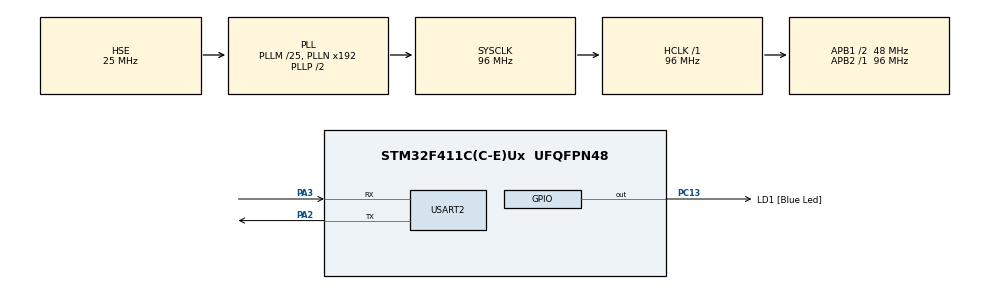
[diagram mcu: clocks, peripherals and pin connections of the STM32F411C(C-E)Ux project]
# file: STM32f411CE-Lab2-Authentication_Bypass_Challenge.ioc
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Mcu.Family=STM32F4
Mcu.Name=STM32F411C(C-E)Ux
Mcu.Package=UFQFPN48
NVIC.PriorityGroup=NVIC_PRIORITYGROUP_4
PA13.Mode=JTAG_5_pins
PA13.Signal=SYS_JTMS-SWDIO
PA14.Mode=JTAG_5_pins
PA14.Signal=SYS_JTCK-SWCLK
PA15.Mode=JTAG_5_pins
PA15.Signal=SYS_JTDI
PA2.Mode=Asynchronous
PA2.Signal=USART2_TX
PA3.Mode=Asynchronous
PA3.Signal=USART2_RX
PB3.Mode=JTAG_5_pins
PB3.Signal=SYS_JTDO-SWO
PB4.Mode=JTAG_5_pins
PB4.Signal=SYS_JTRST
PC13-ANTI_TAMP.GPIO_Label=LD1 [Blue Led]
PC13-ANTI_TAMP.Signal=GPIO_Output
PC14-OSC32_IN.Mode=LSE-External-Oscillator
PC14-OSC32_IN.Signal=RCC_OSC32_IN
PC15-OSC32_OUT.Mode=LSE-External-Oscillator
PC15-OSC32_OUT.Signal=RCC_OSC32_OUT
PH0\ -\ OSC_IN.Mode=HSE-External-Oscillator
PH0\ -\ OSC_IN.Signal=RCC_OSC_IN
PH1\ -\ OSC_OUT.Mode=HSE-External-Oscillator
PH1\ -\ OSC_OUT.Signal=RCC_OSC_OUT
ProjectManager.HeapSize=0x200
ProjectManager.StackSize=0x400
ProjectManager.TargetToolchain=STM32CubeIDE
RCC.48MHZClocksFreq_Value=48000000
RCC.AHBFreq_Value=96000000
RCC.APB1CLKDivider=RCC_HCLK_DIV2
RCC.APB1Freq_Value=48000000
RCC.APB1TimFreq_Value=96000000
RCC.APB2Freq_Value=96000000
RCC.APB2TimFreq_Value=96000000
RCC.CortexFreq_Value=96000000
RCC.HCLKFreq_Value=96000000
RCC.HSE_VALUE=25000000
RCC.HSI_VALUE=16000000
RCC.PLLM=25
RCC.PLLSourceVirtual=RCC_PLLSOURCE_HSE
RCC.SYSCLKFreq_VALUE=96000000
RCC.SYSCLKSource=RCC_SYSCLKSOURCE_PLLCLK
RCC.VCOOutputFreq_Value=192000000
USART2.VirtualMode=VM_ASYNC
board=custom

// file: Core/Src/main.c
/* USER CODE BEGIN Header */
/**
  ******************************************************************************
  * @file           : main.c
  * @brief          : Main program body
  ******************************************************************************
  * @attention
  *
  * Copyright (c) 2025 STMicroelectronics.
  * All rights reserved.
  *
  * This software is licensed under terms that can be found in the LICENSE file
  * in the root directory of this software component.
  * If no LICENSE file comes with this software, it is provided AS-IS.
  *
  ******************************************************************************
  */
/* USER CODE END Header */
#include "main.h"

/* USER CODE BEGIN Includes */

#include "uart_utils.h"
#include "led_control.h"
#include "validate.h"

/* USER CODE END Includes */

/* USER CODE BEGIN PD */

#define SECRET_WORD "india"

/* USER CODE END PD */

UART_HandleTypeDef huart2;

void SystemClock_Config(void);
static void MX_GPIO_Init(void);
static void MX_USART2_UART_Init(void);

int main(void)
{

  /* MCU Configuration--------------------------------------------------------*/

  /* Reset of all peripherals, Initializes the Flash interface and the Systick. */
  HAL_Init();

  /* Configure the system clock */
  SystemClock_Config();

  /* Initialize all configured peripherals */
  MX_GPIO_Init();
  MX_USART2_UART_Init();
  /* USER CODE BEGIN 2 */

  HAL_GPIO_WritePin(GPIOA, GPIO_PIN_5, GPIO_PIN_RESET);
  char input[100];

  /* USER CODE END 2 */

  /* Infinite loop */
  while (1)
  {

    /* USER CODE BEGIN 3 */

	  UART_TransmitString("Enter secret word: ");
	  UART_ReceiveLine(input, sizeof(input));

	  if (validate_answer(input, SECRET_WORD) == 0) {
		  UART_TransmitString("✔ Correct! Blinking LED...\r\n");
	      Blink_LED(25);
	      HAL_GPIO_WritePin(GPIOA, GPIO_PIN_5, GPIO_PIN_RESET);
	  } else {
	      UART_TransmitString("❌ Wrong answer.\r\n");
	      HAL_GPIO_WritePin(GPIOA, GPIO_PIN_5, GPIO_PIN_RESET);
	  }
  }
  /* USER CODE END 3 */
}

void SystemClock_Config(void)
{
  RCC_OscInitTypeDef RCC_OscInitStruct = {0};
  RCC_ClkInitTypeDef RCC_ClkInitStruct = {0};

  /** Configure the main internal regulator output voltage
  */
  __HAL_RCC_PWR_CLK_ENABLE();
  __HAL_PWR_VOLTAGESCALING_CONFIG(PWR_REGULATOR_VOLTAGE_SCALE1);

  /** Initializes the RCC Oscillators according to the specified parameters
  * in the RCC_OscInitTypeDef structure.
  */
  RCC_OscInitStruct.OscillatorType = RCC_OSCILLATORTYPE_HSE;
  RCC_OscInitStruct.HSEState = RCC_HSE_ON;
  RCC_OscInitStruct.PLL.PLLState = RCC_PLL_ON;
  RCC_OscInitStruct.PLL.PLLSource = RCC_PLLSOURCE_HSE;
  RCC_OscInitStruct.PLL.PLLM = 25;
  RCC_OscInitStruct.PLL.PLLN = 192;
  RCC_OscInitStruct.PLL.PLLP = RCC_PLLP_DIV2;
  RCC_OscInitStruct.PLL.PLLQ = 4;
  if (HAL_RCC_OscConfig(&RCC_OscInitStruct) != HAL_OK)
  {
    Error_Handler();
  }

  /** Initializes the CPU, AHB and APB buses clocks
  */
  RCC_ClkInitStruct.ClockType = RCC_CLOCKTYPE_HCLK|RCC_CLOCKTYPE_SYSCLK
                              |RCC_CLOCKTYPE_PCLK1|RCC_CLOCKTYPE_PCLK2;
  RCC_ClkInitStruct.SYSCLKSource = RCC_SYSCLKSOURCE_PLLCLK;
  RCC_ClkInitStruct.AHBCLKDivider = RCC_SYSCLK_DIV1;
  RCC_ClkInitStruct.APB1CLKDivider = RCC_HCLK_DIV2;
  RCC_ClkInitStruct.APB2CLKDivider = RCC_HCLK_DIV1;

  if (HAL_RCC_ClockConfig(&RCC_ClkInitStruct, FLASH_LATENCY_3) != HAL_OK)
  {
    Error_Handler();
  }
}

static void MX_USART2_UART_Init(void)
{

  huart2.Instance = USART2;
  huart2.Init.BaudRate = 115200;
  huart2.Init.WordLength = UART_WORDLENGTH_8B;
  huart2.Init.StopBits = UART_STOPBITS_1;
  huart2.Init.Parity = UART_PARITY_NONE;
  huart2.Init.Mode = UART_MODE_TX_RX;
  huart2.Init.HwFlowCtl = UART_HWCONTROL_NONE;
  huart2.Init.OverSampling = UART_OVERSAMPLING_16;
  if (HAL_UART_Init(&huart2) != HAL_OK)
  {
    Error_Handler();
  }

}

static void MX_GPIO_Init(void)
{
  GPIO_InitTypeDef GPIO_InitStruct = {0};

  /* GPIO Ports Clock Enable */
  __HAL_RCC_GPIOC_CLK_ENABLE();
  __HAL_RCC_GPIOH_CLK_ENABLE();
  __HAL_RCC_GPIOA_CLK_ENABLE();
  __HAL_RCC_GPIOB_CLK_ENABLE();

  /*Configure GPIO pin Output Level */
  HAL_GPIO_WritePin(LD1_GPIO_Port, LD1_Pin, GPIO_PIN_RESET);

  /*Configure GPIO pin : LD1_Pin */
  GPIO_InitStruct.Pin = LD1_Pin;
  GPIO_InitStruct.Mode = GPIO_MODE_OUTPUT_PP;
  GPIO_InitStruct.Pull = GPIO_NOPULL;
  GPIO_InitStruct.Speed = GPIO_SPEED_FREQ_LOW;
  HAL_GPIO_Init(LD1_GPIO_Port, &GPIO_InitStruct);

}

void Error_Handler(void)
{
  __disable_irq();
  while (1)
  {
  }
}
